# ATA5833 device description
Architecture: AVR8; Family: megaAVR
Registers are 8-bit, access not given, no defined reset value unless marked. A register's access mark holds for its fields unless they carry their own. Offsets are from the block's base; [hi:lo] are bit positions; {n}, {i} and the like mark numbered series.

## RXBUF
Instances: RXBUF 0x00
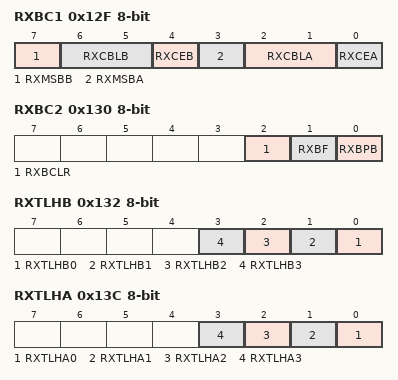
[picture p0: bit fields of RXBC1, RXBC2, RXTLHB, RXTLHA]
0x12F RXBC1 — Rx Buffer configuration register 1
  [7] RXMSBB — Receive Data MSB-first for data path B
  [6:5] RXCBLB — Receive CRC Bit Lengths setting for data path B
    0=CRC_4_BIT; 1=CRC_8_BIT; 2=CRC_16_BIT
  [4] RXCEB — RX CRC Enable data path B
  [3] RXMSBA — Receive Data MSB-first for data path A
  [2:1] RXCBLA — Receive CRC Bit Lengths setting for data path A
    0=CRC_4_BIT; 1=CRC_8_BIT; 2=CRC_16_BIT
  [0] RXCEA — RX CRC Enable data path A
0x130 RXBC2 — Rx Buffer configuration register 2
  [2] RXBCLR — RX Buffer Clear
  [1] RXBF — RX Buffer Finish
  [0] RXBPB — RX Buffer Path B select signal
0x131 RXTLLB — Rx data telegram length register low byte for data path B
0x132 RXTLHB — Rx data telegram length register high byte for data path B
  [n] RXTLHB{n} (n=0..3) — RXTL (Receive Telegram Length) register High byte for data path B bit {n}
0x133 RXCRLB — Rx CRC result register low byte for data path B
0x134 RXCRHB — Rx CRC result register high byte for data path B
0x135 RXCSBB — Rx CRC skip bit number for data path B
0x136 RXCILB — Rx CRC Init value (16-bit RXCI) low byte for data path B
0x137 RXCIHB — Rx CRC Init value (16-bit RXCI) high byte for data path B
0x138 RXCPLB bits used 7:1 — Rx CRC polynomial low byte for data path B
0x139 RXCPHB — Rx CRC polynomial (15 bit RXCPB) high byte for data path B
0x13A RXDSB — Rx data shift register for data path B
0x13B RXTLLA — Rx data telegram length register low byte for data path A
0x13C RXTLHA — Rx data telegram length register high byte for data path A
  [n] RXTLHA{n} (n=0..3) — RXTL (Receive Telegram Length) register High byte for data path A bit {n}
0x13D RXCRLA — Rx CRC result register low byte for data path A
0x13E RXCRHA — Rx CRC result register high byte for data path A
0x13F RXCSBA — Rx CRC skip bit number for data path A
0x140 RXCILA — Rx CRC Init value (16-bit RXCI) low byte for data path A
0x141 RXCIHA — Rx CRC Init value (16-bit RXCI) high byte for data path A
0x142 RXCPLA bits used 7:1 — Rx CRC polynomial low byte for data path A
0x143 RXCPHA — Rx CRC polynomial (15 bit RXCPA) high byte for data path A
0x144 RXDSA — Rx data shift register for data path A

## SFIFO
Instances: SFIFO 0x00
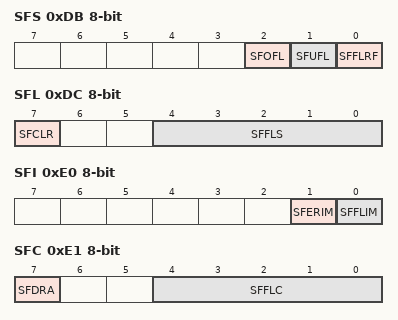
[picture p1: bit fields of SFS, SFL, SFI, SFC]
0xDB SFS — Support FIFO Status Register
  [2] SFOFL — Support FIFO Overflow Flag
  [1] SFUFL — Support FIFO Underflow Flag
  [0] SFFLRF — Support FIFO Fill-Level Reached Status Flag
0xDC SFL — Support FIFO Fill Level Register
  [7] SFCLR — Support FIFO Clear
  [4:0] SFFLS — Support FIFO Fill Level Status
0xDD SFWP — Support FIFO Write Pointer
  [4:0] SFWP
0xDE SFRP — Support FIFO Read Pointer
  [4:0] SFRP
0xDF SFD — Support FIFO Data Register
0xE0 SFI — Support FIFO Interrupt Mask Register
  [1] SFERIM — Support FIFO Error Interrupt Mask
  [0] SFFLIM — Support FIFO Fill-level Interrupt Mask
0xE1 SFC — Support FIFO Configuration Register
  [7] SFDRA — Support FIFO Direct Read Access Operational Mode
  [4:0] SFFLC — Support FIFO Fill-Level Configuration

## SPI
Instances: SPI 0x00
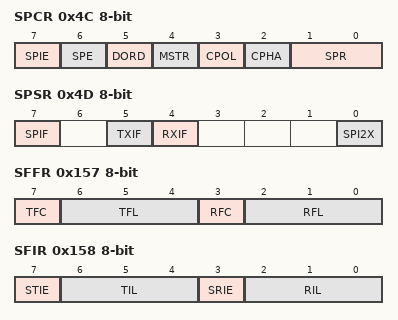
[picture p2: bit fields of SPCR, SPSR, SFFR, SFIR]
0x4C SPCR — SPI Control Register
  [7] SPIE — SPI Interrupt Enable
  [6] SPE — SPI Enable
  [5] DORD — Data Order
  [4] MSTR — Master/Slave Select
  [3] CPOL — Clock polarity
  [2] CPHA — Clock Phase
  [1:0] SPR — SPI Clock Rate Selects
    0=CLKIO_4; 1=CLKIO_16; 2=CLKIO_64; 3=CLKIO_128; 4=CLKIO_2; 5=CLKIO_8; 6=CLKIO_32; 7=CLKIO_64
0x4D SPSR — SPI Status Register
  [7] SPIF — SPI Interrupt Flag
  [5] TXIF — Tx Buffer Interrupt Flag
  [4] RXIF — Rx Buffer Interrupt Flag
  [0] SPI2X — Double SPI Speed Bit
0x4E SPDR — SPI Data Register
0x157 SFFR — SPI FIFO Fill Status Register
  [7] TFC — SPI Tx Buffer Clear
  [6:4] TFL — SPI Transmit Buffer Fill Level
  [3] RFC — SPI Rx Buffer Clear
  [2:0] RFL — SPI Receive Buffer Fill Level
0x158 SFIR — SPI FIFO Interrupt Register
  [7] STIE — SPI Tx Buffer Interrupt Enable
  [6:4] TIL — SPI Transmit Buffer Interrupt Level
  [3] SRIE — SPI Rx Buffer Interrupt Enable
  [2:0] RIL — SPI Receive Buffer Interrupt Level
